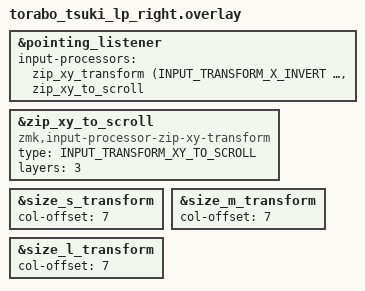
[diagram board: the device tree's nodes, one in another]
#include "torabo_tsuki_lp.dtsi"
#include <input/processors.dtsi>
#include <dt-bindings/zmk/input_transform.h>

&pointing_listener {
    input-processors =
        <&zip_xy_transform (INPUT_TRANSFORM_X_INVERT | INPUT_TRANSFORM_Y_INVERT)>
        , <&zip_xy_to_scroll>;
};

&zip_xy_to_scroll {
    compatible = "zmk,input-processor-zip-xy-transform";
    type = <INPUT_TRANSFORM_XY_TO_SCROLL>;
    layers = <3>;   // ← こっちでレイヤー制御（推奨）
};

&size_s_transform {
    col-offset = <7>;
};

&size_m_transform {
    col-offset = <7>;
};

&size_l_transform {
    col-offset = <7>;
};
